VERSION ""

NS_ :

BS_:
BU_: Current
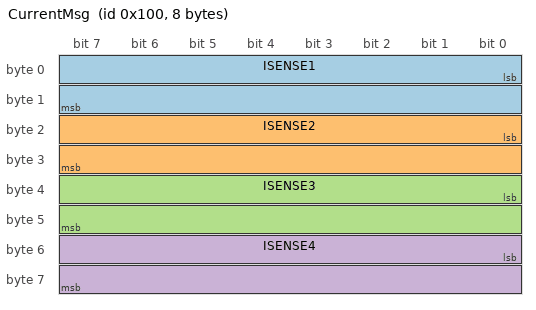
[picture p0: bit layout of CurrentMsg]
BO_ 256 CurrentMsg: 8 Current
   SG_ ISENSE1 : 0|16@1+ (1,0) [0|65535] "counts" Vector__XXX
   SG_ ISENSE2 : 16|16@1+ (1,0) [0|1] "" Vector__XXX
   SG_ ISENSE3 : 32|16@1+ (1,0) [0|1] "" Vector__XXX
   SG_ ISENSE4 : 48|16@1+ (1,0) [0|1] "" Vector__XXX

BA_DEF_ BO_ "GenMsgBackgroundColor" STRING ;
BA_DEF_ BO_ "GenMsgForegroundColor" STRING ;
BA_DEF_ BO_ "filterlabeling" INT 0 0;
BA_DEF_DEF_ "GenMsgBackgroundColor" "#ffffff";
BA_DEF_DEF_ "GenMsgForegroundColor" "#232629";
BA_DEF_DEF_ "filterlabeling" 1;
